# RX64M_DMAC_Pilot register map
File version: 1.0
RX64M_DMAC_Pilot peripheral registers generated from iodefine.h (pilot).
Registers are 8-bit, read-write, reset 0x0 unless marked. A register's access mark holds for its fields unless they carry their own. Offsets are from the block's base; lines under a group give offsets from that group; [hi:lo] are bit positions; {n}, {i} and the like mark numbered series; 'fields as' and 'values as' point back to an identical list; <NAME> marks a mode.

## Memory map
0x00082200 DMAC size 0x5

## DMAC
Base 0x00082200
0x00 DMAST
  [0] DMST
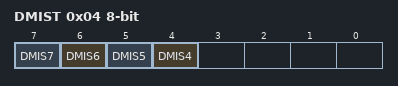
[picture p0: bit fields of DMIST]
0x04 DMIST ro
  [n] DMIS{n} (n=4..7)
